# f28p65x_cpu1_periph_ac_regs register map
Vendor: Texas Instruments
Peripheral module from a debugger description file (folder C2000).
Address unit: 16 bits
Registers are 32-bit, read-write, no defined reset value unless marked. A register's access mark holds for its fields unless they carry their own. Offsets are as the file gives them; lines under a group give offsets from that group; [hi:lo] are bit positions; {n}, {i} and the like mark numbered series; 'fields as' and 'values as' point back to an identical list; <NAME> marks a mode.

## CPU1_PERIPH_AC_REGS — CPU1 PERIPH AC Registers
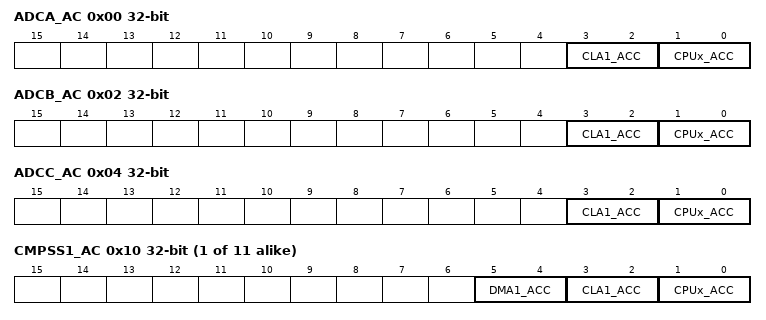
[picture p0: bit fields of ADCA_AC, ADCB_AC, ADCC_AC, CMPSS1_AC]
0x00 ADCA_AC — ADCA Controller Access Control Register
  [3:2] CLA1_ACC — CLA1 Access Conditions to Peripheral
  [1:0] CPUx_ACC — CPUx Access conditions to peripheral
0x02 ADCB_AC — ADCB Controller Access Control Register
  fields as ADCA_AC
0x04 ADCC_AC — ADCC Controller Access Control Register
  fields as ADCA_AC
{0xE+2i} CMPSS{i}_AC (i=1..11) — CMPSS{i} Controller Access Control Register
  [5:4] DMA1_ACC — DMA1 Access Conditions to Peripheral
  [3:2] CLA1_ACC — CLA1 Access Conditions to Peripheral
  [1:0] CPUx_ACC — CPUx Access conditions to peripheral
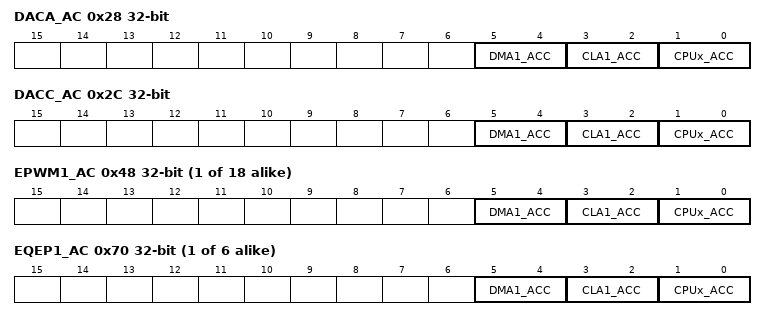
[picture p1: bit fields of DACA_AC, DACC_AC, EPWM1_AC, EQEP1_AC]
0x28 DACA_AC — DACA Controller Access Control Register
  fields as CMPSS1_AC
0x2C DACC_AC — DACC Controller Access Control Register
  fields as CMPSS1_AC
{0x46+2i} EPWM{i}_AC (i=1..18) — EPWM{i} Controller Access Control Register
  fields as CMPSS1_AC
{0x6E+2i} EQEP{i}_AC (i=1..6) — EQEP{i} Controller Access Control Register
  fields as CMPSS1_AC
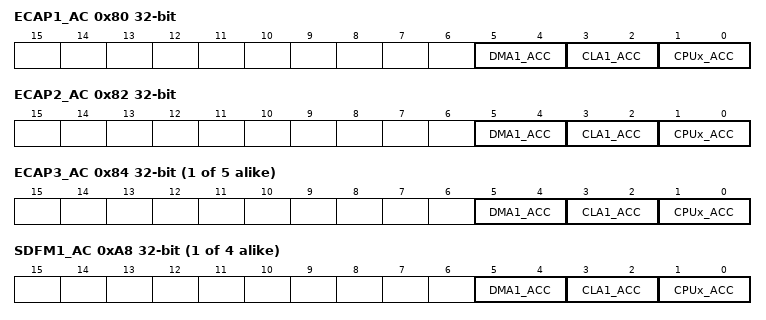
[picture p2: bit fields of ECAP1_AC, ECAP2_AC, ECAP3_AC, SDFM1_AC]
0x80 ECAP1_AC — ECAP1 Controller Access Control Register
  fields as CMPSS1_AC
0x82 ECAP2_AC — ECAP2 Controller Access Control Register
  [5:4] DMA1_ACC — DMA1 Access Conditions to Peripheral
  [3:2] CLA1_ACC — CLA1 Access Conditions to Peripheral
  [1:0] CPUx_ACC — CPUx Access c+D2593onditions to peripheral
{0x7E+2i} ECAP{i}_AC (i=3..7) — ECAP{i} Controller Access Control Register
  fields as CMPSS1_AC
{0xA6+2i} SDFM{i}_AC (i=1..4) — SDFM{i} Controller Access Control Register
  fields as CMPSS1_AC
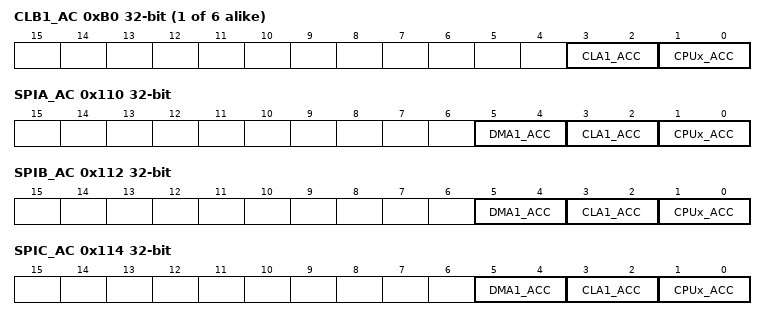
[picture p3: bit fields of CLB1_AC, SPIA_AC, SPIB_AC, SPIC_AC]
{0xAE+2i} CLB{i}_AC (i=1..6) — CLB{i} Controller Access Control Register
  fields as ADCA_AC
0x100 SCIA_AC — SCIA Controller Access Control Register
  [1:0] CPUx_ACC — CPUx Access conditions to peripheral
0x102 SCIB_AC — SCIB Controller Access Control Register
  [1:0] CPUx_ACC — CPUx Access conditions to peripheral
0x110 SPIA_AC — SPIA Controller Access Control Register
  fields as CMPSS1_AC
0x112 SPIB_AC — SPIB Controller Access Control Register
  fields as CMPSS1_AC
0x114 SPIC_AC — SPIC Controller Access Control Register
  fields as CMPSS1_AC
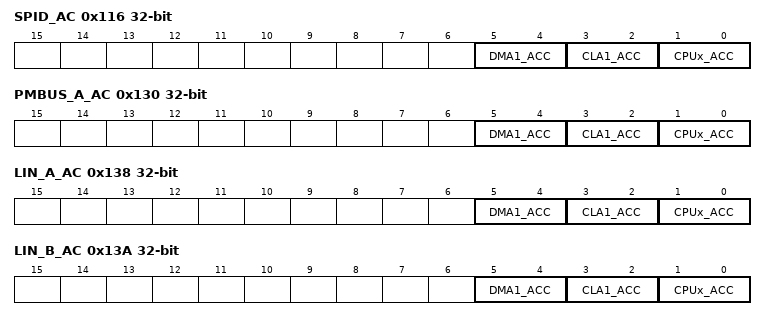
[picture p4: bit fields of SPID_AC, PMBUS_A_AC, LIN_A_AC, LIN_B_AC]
0x116 SPID_AC — SPID Controller Access Control Register
  fields as CMPSS1_AC
0x120 I2CA_AC — I2CA Controller Access Control Register
  [1:0] CPUx_ACC — CPUx Access conditions to peripheral
0x122 I2CB_AC — I2CB Controller Access Control Register
  [1:0] CPUx_ACC — CPUx Access conditions to peripheral
0x130 PMBUS_A_AC — PMBUSA Controller Access Control Register
  fields as CMPSS1_AC
0x138 LIN_A_AC — LINA Controller Access Control Register
  fields as CMPSS1_AC
0x13A LIN_B_AC — LINB Controller Access Control Register
  fields as CMPSS1_AC
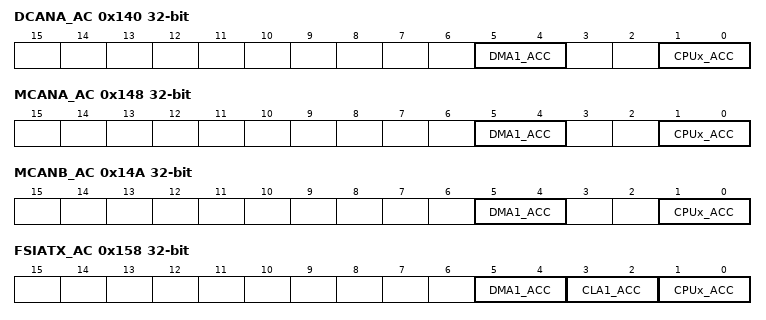
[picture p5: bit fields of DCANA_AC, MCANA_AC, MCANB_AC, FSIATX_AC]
0x140 DCANA_AC — DCANA Controller Access Control Register
  [5:4] DMA1_ACC — DMA1 Access Conditions to Peripheral
  [1:0] CPUx_ACC — CPUx Access conditions to peripheral
0x148 MCANA_AC — MCANA Controller Access Control Register
  fields as DCANA_AC
0x14A MCANB_AC — MCANB Controller Access Control Register
  fields as DCANA_AC
0x158 FSIATX_AC — FSIA Controller Access Control Register
  fields as CMPSS1_AC
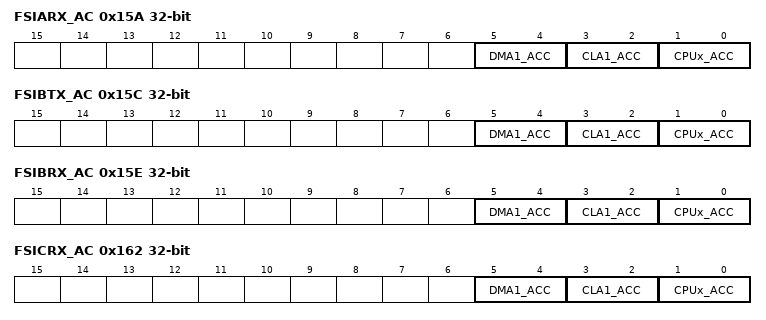
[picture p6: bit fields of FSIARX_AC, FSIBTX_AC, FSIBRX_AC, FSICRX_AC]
0x15A FSIARX_AC — FSIB Controller Access Control Register
  fields as CMPSS1_AC
0x15C FSIBTX_AC — FSIC Controller Access Control Register
  fields as CMPSS1_AC
0x15E FSIBRX_AC — FSID Controller Access Control Register
  fields as CMPSS1_AC
0x162 FSICRX_AC — FSIB Controller Access Control Register
  fields as CMPSS1_AC
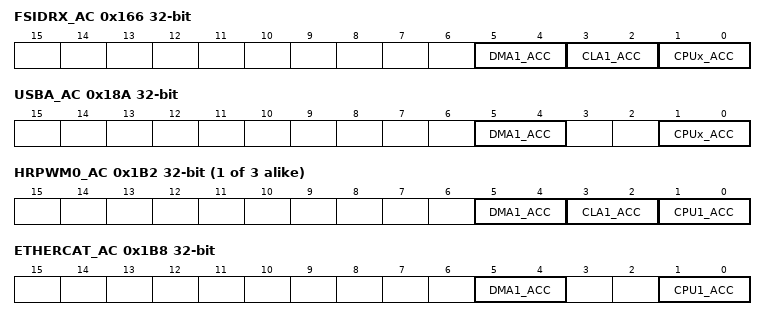
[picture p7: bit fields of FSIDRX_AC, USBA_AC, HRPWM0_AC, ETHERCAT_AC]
0x166 FSIDRX_AC — FSID Controller Access Control Register
  fields as CMPSS1_AC
0x18A USBA_AC — USBA Controller Access Control Register
  fields as DCANA_AC
{0x1B2+2i} HRPWM{i}_AC (i=0..2) — HRPWM Controller Access Control Register
  [5:4] DMA1_ACC — DMA1 Access Conditions to Peripheral
  [3:2] CLA1_ACC — CLA1 Access Conditions to Peripheral
  [1:0] CPU1_ACC — CPU1 Access conditions to peripheral
0x1B8 ETHERCAT_AC — ETHERCAT Controller Access Control Register
  [5:4] DMA1_ACC — DMA1 Access Conditions to Peripheral
  [1:0] CPU1_ACC — CPU1 Access conditions to peripheral
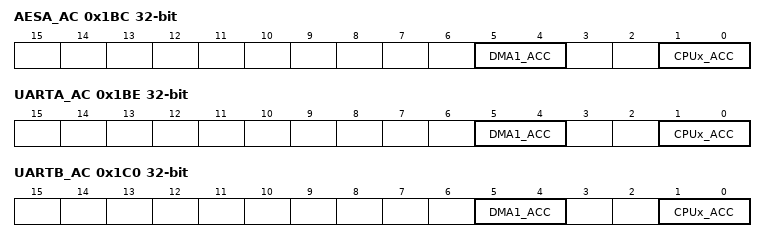
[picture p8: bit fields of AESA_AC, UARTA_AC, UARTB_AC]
0x1BC AESA_AC — AES Controller Access Control Register
  fields as DCANA_AC
0x1BE UARTA_AC — UART Controller Access Control Register
  fields as DCANA_AC
0x1C0 UARTB_AC — UART Controller Access Control Register
  fields as DCANA_AC
0x1FE PERIPH_AC_LOCK — Lock Register to stop Write access to peripheral Access register.
  [0] LOCK_AC_WR — Lock control for Access control registers write.
